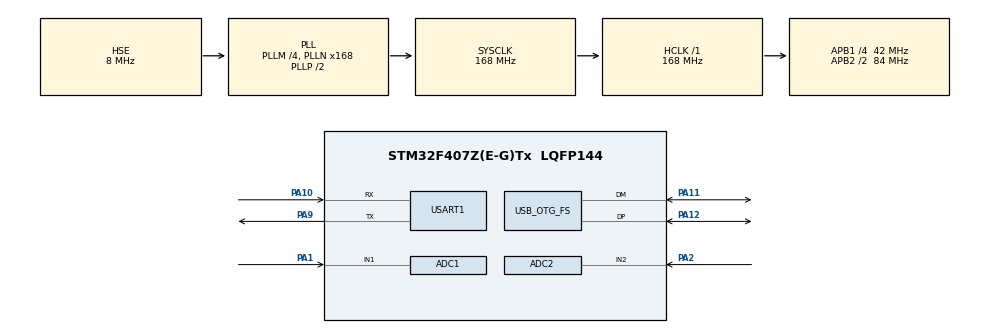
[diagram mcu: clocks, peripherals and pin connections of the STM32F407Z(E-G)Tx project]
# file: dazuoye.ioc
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ADC1.Channel-0\#ChannelRegularConversion=ADC_CHANNEL_1
ADC1.ExternalTrigConv=ADC_EXTERNALTRIGCONV_T2_TRGO
ADC1.NbrOfConversionFlag=1
ADC1.Rank-0\#ChannelRegularConversion=1
ADC1.SamplingTime-0\#ChannelRegularConversion=ADC_SAMPLETIME_3CYCLES
ADC1.master=1
ADC2.Channel-0\#ChannelRegularConversion=ADC_CHANNEL_2
ADC2.ExternalTrigConv=ADC_EXTERNALTRIGCONV_T3_TRGO
ADC2.NbrOfConversionFlag=1
ADC2.Rank-0\#ChannelRegularConversion=1
ADC2.SamplingTime-0\#ChannelRegularConversion=ADC_SAMPLETIME_3CYCLES
Dma.ADC1.0.Direction=DMA_PERIPH_TO_MEMORY
Dma.ADC1.0.FIFOMode=DMA_FIFOMODE_DISABLE
Dma.ADC1.0.Instance=DMA2_Stream0
Dma.ADC1.0.MemDataAlignment=DMA_MDATAALIGN_HALFWORD
Dma.ADC1.0.MemInc=DMA_MINC_ENABLE
Dma.ADC1.0.Mode=DMA_NORMAL
Dma.ADC1.0.PeriphDataAlignment=DMA_PDATAALIGN_HALFWORD
Dma.ADC1.0.PeriphInc=DMA_PINC_DISABLE
Dma.ADC1.0.Priority=DMA_PRIORITY_LOW
Dma.ADC2.1.Direction=DMA_PERIPH_TO_MEMORY
Dma.ADC2.1.FIFOMode=DMA_FIFOMODE_DISABLE
Dma.ADC2.1.Instance=DMA2_Stream2
Dma.ADC2.1.MemDataAlignment=DMA_MDATAALIGN_HALFWORD
Dma.ADC2.1.MemInc=DMA_MINC_ENABLE
Dma.ADC2.1.Mode=DMA_NORMAL
Dma.ADC2.1.PeriphDataAlignment=DMA_PDATAALIGN_HALFWORD
Dma.ADC2.1.PeriphInc=DMA_PINC_DISABLE
Dma.ADC2.1.Priority=DMA_PRIORITY_LOW
Dma.Request0=ADC1
Dma.Request1=ADC2
Dma.Request2=USART1_TX
Dma.USART1_TX.2.Direction=DMA_MEMORY_TO_PERIPH
Dma.USART1_TX.2.FIFOMode=DMA_FIFOMODE_DISABLE
Dma.USART1_TX.2.Instance=DMA2_Stream7
Dma.USART1_TX.2.MemDataAlignment=DMA_MDATAALIGN_BYTE
Dma.USART1_TX.2.MemInc=DMA_MINC_ENABLE
Dma.USART1_TX.2.Mode=DMA_NORMAL
Dma.USART1_TX.2.PeriphDataAlignment=DMA_PDATAALIGN_BYTE
Dma.USART1_TX.2.PeriphInc=DMA_PINC_DISABLE
Dma.USART1_TX.2.Priority=DMA_PRIORITY_LOW
FREERTOS.Tasks01=Task_ADC1,0,512,StartDefaultTask,Default,NULL,Dynamic,NULL,NULL;Task_ADC2,0,512,StartTask02,Default,NULL,Dynamic,NULL,NULL
Mcu.Family=STM32F4
Mcu.Name=STM32F407Z(E-G)Tx
Mcu.Package=LQFP144
NVIC.DMA2_Stream0_IRQn=true\:5\:0\:false\:false\:true\:true\:false\:true\:true
NVIC.DMA2_Stream2_IRQn=true\:5\:0\:false\:false\:true\:true\:false\:true\:true
NVIC.DMA2_Stream7_IRQn=true\:5\:0\:false\:false\:true\:true\:false\:true\:true
NVIC.OTG_FS_IRQn=true\:5\:0\:false\:false\:true\:true\:false\:true\:true
NVIC.PriorityGroup=NVIC_PRIORITYGROUP_4
NVIC.TIM6_DAC_IRQn=true\:15\:0\:false\:false\:true\:false\:false\:true\:true
NVIC.TimeBase=TIM6_DAC_IRQn
NVIC.TimeBaseIP=TIM6
NVIC.USART1_IRQn=true\:5\:0\:false\:false\:true\:true\:false\:true\:true
PA1.Signal=ADCx_IN1
PA10.Mode=Asynchronous
PA10.Signal=USART1_RX
PA11.Mode=Device_Only
PA11.Signal=USB_OTG_FS_DM
PA12.Mode=Device_Only
PA12.Signal=USB_OTG_FS_DP
PA13.Mode=Serial_Wire
PA13.Signal=SYS_JTMS-SWDIO
PA14.Mode=Serial_Wire
PA14.Signal=SYS_JTCK-SWCLK
PA2.Signal=ADCx_IN2
PA9.Mode=Asynchronous
PA9.Signal=USART1_TX
PH0-OSC_IN.Mode=HSE-External-Oscillator
PH0-OSC_IN.Signal=RCC_OSC_IN
PH1-OSC_OUT.Mode=HSE-External-Oscillator
PH1-OSC_OUT.Signal=RCC_OSC_OUT
ProjectManager.HeapSize=0x200
ProjectManager.StackSize=0x400
ProjectManager.TargetToolchain=MDK-ARM V5.32
RCC.48MHZClocksFreq_Value=48000000
RCC.AHBFreq_Value=168000000
RCC.APB1CLKDivider=RCC_HCLK_DIV4
RCC.APB1Freq_Value=42000000
RCC.APB1TimFreq_Value=84000000
RCC.APB2CLKDivider=RCC_HCLK_DIV2
RCC.APB2Freq_Value=84000000
RCC.APB2TimFreq_Value=168000000
RCC.CortexFreq_Value=168000000
RCC.HCLKFreq_Value=168000000
RCC.HSE_VALUE=8000000
RCC.HSI_VALUE=16000000
RCC.LSE_VALUE=32768
RCC.PLLM=4
RCC.PLLN=168
RCC.PLLQ=7
RCC.SYSCLKFreq_VALUE=168000000
RCC.SYSCLKSource=RCC_SYSCLKSOURCE_PLLCLK
RCC.VCOOutputFreq_Value=336000000
SH.ADCx_IN1.0=ADC1_IN1,IN1
SH.ADCx_IN2.0=ADC2_IN2,IN2
TIM2.Period=1000-1
TIM2.Prescaler=84-1
TIM2.TIM_MasterOutputTrigger=TIM_TRGO_UPDATE
TIM3.Period=1000-1
TIM3.Prescaler=28-1
TIM3.TIM_MasterOutputTrigger=TIM_TRGO_UPDATE
USART1.VirtualMode=VM_ASYNC
USB_DEVICE.CLASS_NAME_FS=CDC
USB_DEVICE.VirtualMode-CDC_FS=Cdc
USB_DEVICE.VirtualModeFS=Cdc_FS
USB_OTG_FS.VirtualMode=Device_Only
VP_FREERTOS_VS_CMSIS_V1.Mode=CMSIS_V1
VP_SYS_VS_tim6.Mode=TIM6
VP_TIM2_VS_ClockSourceINT.Mode=Internal
VP_TIM3_VS_ClockSourceINT.Mode=Internal
VP_USB_DEVICE_VS_USB_DEVICE_CDC_FS.Mode=CDC_FS
board=custom

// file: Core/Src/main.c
/* USER CODE BEGIN Header */
/**
  ******************************************************************************
  * @file           : main.c
  * @brief          : Main program body
  ******************************************************************************
  * @attention
  *
  * Copyright (c) 2026 STMicroelectronics.
  * All rights reserved.
  *
  * This software is licensed under terms that can be found in the LICENSE file
  * in the root directory of this software component.
  * If no LICENSE file comes with this software, it is provided AS-IS.
  *
  ******************************************************************************
  */
/* USER CODE END Header */
#include "main.h"
#include "cmsis_os.h"
#include "adc.h"
#include "dma.h"
#include "tim.h"
#include "usart.h"
#include "usb_device.h"
#include "gpio.h"

/* USER CODE BEGIN Includes */
/* USB Device CDC init function (generated by CubeMX after enabling USB_DEVICE) */
void MX_USB_DEVICE_Init(void);

/* USER CODE END Includes */

void SystemClock_Config(void);
void MX_FREERTOS_Init(void);

/* USER CODE BEGIN 0 */
/*
 * Weak fallback: build is linkable before CubeMX generates usb_device.c.
 */
__weak void MX_USB_DEVICE_Init(void)
{
}

/* USER CODE END 0 */

int main(void)
{

  /* MCU Configuration--------------------------------------------------------*/

  /* Reset of all peripherals, Initializes the Flash interface and the Systick. */
  HAL_Init();

  /* Configure the system clock */
  SystemClock_Config();

  /* Initialize all configured peripherals */
  MX_GPIO_Init();
  MX_DMA_Init();
  MX_ADC1_Init();
  MX_TIM2_Init();
  MX_TIM3_Init();
  MX_ADC2_Init();
  MX_USART1_UART_Init();

  /* Call init function for freertos objects (in cmsis_os2.c) */
  MX_FREERTOS_Init();

  /* Start scheduler */
  osKernelStart();

  /* We should never get here as control is now taken by the scheduler */

  /* Infinite loop */
  while (1)
  {

  }
}

void SystemClock_Config(void)
{
  RCC_OscInitTypeDef RCC_OscInitStruct = {0};
  RCC_ClkInitTypeDef RCC_ClkInitStruct = {0};

  /** Configure the main internal regulator output voltage
  */
  __HAL_RCC_PWR_CLK_ENABLE();
  __HAL_PWR_VOLTAGESCALING_CONFIG(PWR_REGULATOR_VOLTAGE_SCALE1);

  /** Initializes the RCC Oscillators according to the specified parameters
  * in the RCC_OscInitTypeDef structure.
  */
  RCC_OscInitStruct.OscillatorType = RCC_OSCILLATORTYPE_HSE;
  RCC_OscInitStruct.HSEState = RCC_HSE_ON;
  RCC_OscInitStruct.PLL.PLLState = RCC_PLL_ON;
  RCC_OscInitStruct.PLL.PLLSource = RCC_PLLSOURCE_HSE;
  RCC_OscInitStruct.PLL.PLLM = 4;
  RCC_OscInitStruct.PLL.PLLN = 168;
  RCC_OscInitStruct.PLL.PLLP = RCC_PLLP_DIV2;
  RCC_OscInitStruct.PLL.PLLQ = 7;
  if (HAL_RCC_OscConfig(&RCC_OscInitStruct) != HAL_OK)
  {
    Error_Handler();
  }

  /** Initializes the CPU, AHB and APB buses clocks
  */
  RCC_ClkInitStruct.ClockType = RCC_CLOCKTYPE_HCLK|RCC_CLOCKTYPE_SYSCLK
                              |RCC_CLOCKTYPE_PCLK1|RCC_CLOCKTYPE_PCLK2;
  RCC_ClkInitStruct.SYSCLKSource = RCC_SYSCLKSOURCE_PLLCLK;
  RCC_ClkInitStruct.AHBCLKDivider = RCC_SYSCLK_DIV1;
  RCC_ClkInitStruct.APB1CLKDivider = RCC_HCLK_DIV4;
  RCC_ClkInitStruct.APB2CLKDivider = RCC_HCLK_DIV2;

  if (HAL_RCC_ClockConfig(&RCC_ClkInitStruct, FLASH_LATENCY_5) != HAL_OK)
  {
    Error_Handler();
  }
}

void HAL_TIM_PeriodElapsedCallback(TIM_HandleTypeDef *htim)
{
  if (htim->Instance == TIM6)
  {
    HAL_IncTick();
  }
}

void Error_Handler(void)
{
  __disable_irq();
  while (1)
  {
  }
}

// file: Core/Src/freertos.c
/* USER CODE BEGIN Header */
/**
  ******************************************************************************
  * File Name          : freertos.c
  * Description        : Code for freertos applications
  ******************************************************************************
  * @attention
  *
  * Copyright (c) 2026 STMicroelectronics.
  * All rights reserved.
  *
  * This software is licensed under terms that can be found in the LICENSE file
  * in the root directory of this software component.
  * If no LICENSE file comes with this software, it is provided AS-IS.
  *
  ******************************************************************************
  */
/* USER CODE END Header */

#include "FreeRTOS.h"
#include "task.h"
#include "main.h"
#include "cmsis_os.h"

/* USER CODE BEGIN Includes */
/* 用户功能模块：ADC 采样与 VOFA 串口发送 */
#include "../../UserCode/adc_vofa_user.h"
#include "../../UserCode/adc_vofa_user.c"

/* USER CODE END Includes */

osThreadId Task_ADC1Handle;
osThreadId Task_ADC2Handle;

void StartDefaultTask(void const * argument);
void StartTask02(void const * argument);

extern void MX_USB_DEVICE_Init(void);
void MX_FREERTOS_Init(void); /* (MISRA C 2004 rule 8.1) */

/* GetIdleTaskMemory prototype (linked to static allocation support) */
void vApplicationGetIdleTaskMemory( StaticTask_t **ppxIdleTaskTCBBuffer, StackType_t **ppxIdleTaskStackBuffer, uint32_t *pulIdleTaskStackSize );

/* USER CODE BEGIN GET_IDLE_TASK_MEMORY */
static StaticTask_t xIdleTaskTCBBuffer;                     // 空闲任务控制块静态分配
static StackType_t xIdleStack[configMINIMAL_STACK_SIZE];    // 空闲任务堆栈静态分配

void vApplicationGetIdleTaskMemory( StaticTask_t **ppxIdleTaskTCBBuffer, StackType_t **ppxIdleTaskStackBuffer, uint32_t *pulIdleTaskStackSize )
{
  *ppxIdleTaskTCBBuffer = &xIdleTaskTCBBuffer;
  *ppxIdleTaskStackBuffer = &xIdleStack[0];
  *pulIdleTaskStackSize = configMINIMAL_STACK_SIZE;
  /* place for user code */
}
/* USER CODE END GET_IDLE_TASK_MEMORY */

void MX_FREERTOS_Init(void) {
  /* USER CODE BEGIN Init */
  /* 初始化用户采样模块 */
  UserAdcVofa_Init();

  /* USER CODE END Init */

  /* Create the thread(s) */
  /* definition and creation of Task_ADC1 */
  osThreadDef(Task_ADC1, StartDefaultTask, osPriorityNormal, 0, 512);
  Task_ADC1Handle = osThreadCreate(osThread(Task_ADC1), NULL);

  /* definition and creation of Task_ADC2 */
  osThreadDef(Task_ADC2, StartTask02, osPriorityNormal, 0, 512);
  Task_ADC2Handle = osThreadCreate(osThread(Task_ADC2), NULL);

}

/* USER CODE BEGIN Header_StartDefaultTask */
/**
  * @brief  ADC1 任务线程入口函数
  * @param  argument 线程参数
  * @retval 无
  */
/* USER CODE END Header_StartDefaultTask */
void StartDefaultTask(void const * argument)
{
  /* init code for USB_DEVICE */
  MX_USB_DEVICE_Init();
  /* USER CODE BEGIN StartDefaultTask */
  /* 运行 ADC1 周期采样任务 */
  UserAdcVofa_TaskAdc1(argument);
  /* USER CODE END StartDefaultTask */
}

/* USER CODE BEGIN Header_StartTask02 */
/**
  * @brief  ADC2 任务线程入口函数
  * @param  argument 线程参数
  * @retval 无
  */
/* USER CODE END Header_StartTask02 */
void StartTask02(void const * argument)
{
  /* USER CODE BEGIN StartTask02 */
  /* 运行 ADC2 周期采样任务 */
  UserAdcVofa_TaskAdc2(argument);
  /* USER CODE END StartTask02 */
}

/* USER CODE BEGIN Application */
// ADC转换完成中断回调
void HAL_ADC_ConvCpltCallback(ADC_HandleTypeDef *hadc)
{
  /* 转发到用户模块处理 DMA 采样完成事件 */
  UserAdcVofa_ConvCpltCallback(hadc);
}

/* USER CODE END Application */
